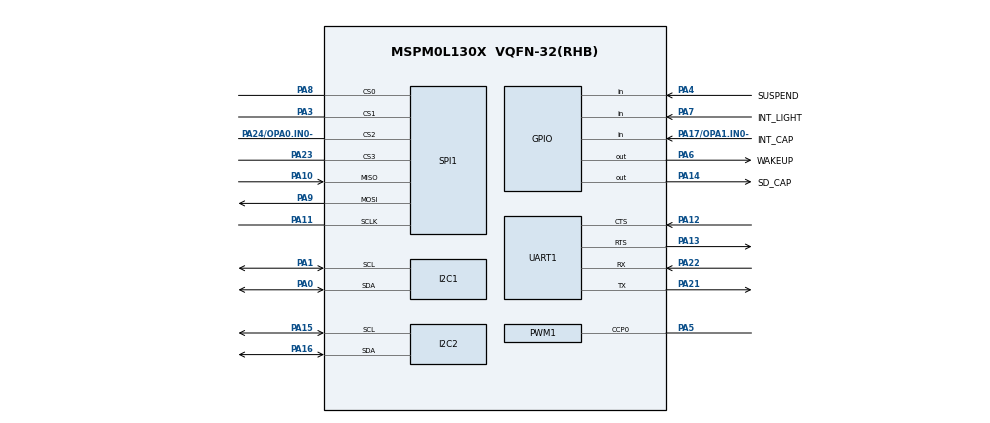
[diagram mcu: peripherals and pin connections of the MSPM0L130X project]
/**
 * @cliArgs --device "MSPM0L130X" --part "Default" --package "VQFN-32(RHB)" --product "mspm0_sdk@2.03.00.08"
 * @versions {"tool":"1.22.0+3893"}
 */

/**
 * Import the modules used in this configuration.
 */
const GPIO   = scripting.addModule("/ti/driverlib/GPIO", {}, false);
const GPIO1  = GPIO.addInstance();
const I2C    = scripting.addModule("/ti/driverlib/I2C", {}, false);
const I2C1   = I2C.addInstance();
const I2C2   = I2C.addInstance();
const PWM    = scripting.addModule("/ti/driverlib/PWM", {}, false);
const PWM1   = PWM.addInstance();
const SPI    = scripting.addModule("/ti/driverlib/SPI", {}, false);
const SPI1   = SPI.addInstance();
const SYSCTL = scripting.addModule("/ti/driverlib/SYSCTL");
const UART   = scripting.addModule("/ti/driverlib/UART", {}, false);
const UART1  = UART.addInstance();

/**
 * Write custom configuration values to the imported modules.
 */
GPIO1.$name                          = "GPIO_INT";
GPIO1.associatedPins.create(9);
GPIO1.associatedPins[0].$name        = "BUT_POS";
GPIO1.associatedPins[0].direction    = "INPUT";
GPIO1.associatedPins[0].ioStructure  = "SD";
GPIO1.associatedPins[0].assignedPin  = "27";
GPIO1.associatedPins[1].$name        = "BUT_ANZ";
GPIO1.associatedPins[1].direction    = "INPUT";
GPIO1.associatedPins[1].assignedPin  = "18";
GPIO1.associatedPins[2].$name        = "INT2_ACC";
GPIO1.associatedPins[2].direction    = "INPUT";
GPIO1.associatedPins[2].assignedPin  = "26";
GPIO1.associatedPins[3].$name        = "INT1_ACC";
GPIO1.associatedPins[3].direction    = "INPUT";
GPIO1.associatedPins[3].assignedPin  = "25";
GPIO1.associatedPins[4].$name        = "INT_CAP";
GPIO1.associatedPins[4].assignedPin  = "17";
GPIO1.associatedPins[4].direction    = "INPUT";
GPIO1.associatedPins[4].pin.$assign  = "PA17/OPA1.IN0-";
GPIO1.associatedPins[5].$name        = "SD_CAP";
GPIO1.associatedPins[5].initialValue = "SET";
GPIO1.associatedPins[5].ioStructure  = "SD";
GPIO1.associatedPins[5].pin.$assign  = "PA14";
GPIO1.associatedPins[6].$name        = "INT_LIGHT";
GPIO1.associatedPins[6].direction    = "INPUT";
GPIO1.associatedPins[6].ioStructure  = "SD";
GPIO1.associatedPins[6].pin.$assign  = "PA7";
GPIO1.associatedPins[7].$name        = "WAKEUP";
GPIO1.associatedPins[7].pin.$assign  = "PA6";
GPIO1.associatedPins[8].$name        = "SUSPEND";
GPIO1.associatedPins[8].direction    = "INPUT";
GPIO1.associatedPins[8].pin.$assign  = "PA4";

const Board = scripting.addModule("/ti/driverlib/Board", {}, false);

I2C1.$name                           = "I2C_0";
I2C1.basicEnableController           = true;
I2C1.basicControllerStandardBusSpeed = "Fast";
I2C1.peripheral.$assign              = "I2C0";
I2C1.peripheral.sdaPin.$assign       = "PA0";
I2C1.peripheral.sclPin.$assign       = "PA1";
I2C1.sdaPinConfig.$name              = "ti_driverlib_gpio_GPIOPinGeneric7";
I2C1.sclPinConfig.$name              = "ti_driverlib_gpio_GPIOPinGeneric8";

I2C2.$name                           = "I2C_1";
I2C2.basicEnableController           = true;
I2C2.basicControllerStandardBusSpeed = "Fast";
I2C2.peripheral.$assign              = "I2C1";
I2C2.peripheral.sdaPin.$assign       = "PA16";
I2C2.peripheral.sclPin.$assign       = "PA15";
I2C2.sdaPinConfig.$name              = "ti_driverlib_gpio_GPIOPinGeneric9";
I2C2.sclPinConfig.$name              = "ti_driverlib_gpio_GPIOPinGeneric10";

PWM1.$name                      = "PWM_0";
PWM1.profile                    = "basic_single_channel_center_align";
PWM1.peripheral.$assign         = "TIMG0";
PWM1.peripheral.ccp0Pin.$assign = "PA5";
PWM1.PWM_CHANNEL_0.$name        = "ti_driverlib_pwm_PWMTimerCC0";
PWM1.ccp0PinConfig.$name        = "ti_driverlib_gpio_GPIOPinGeneric15";

SPI1.$name                              = "SPI_0";
SPI1.targetBitRate                      = 1000000;
SPI1.enableDMAEvent1                    = false;
SPI1.enableDMAEvent2                    = false;
SPI1.mode                               = "CONTROLLER";
SPI1.chipSelect                         = ["0","1","2","3"];
SPI1.peripheral.sclkPin.$assign         = "PA11";
SPI1.peripheral.mosiPin.$assign         = "PA9";
SPI1.peripheral.misoPin.$assign         = "PA10";
SPI1.peripheral.cs0Pin.$assign          = "PA8";
SPI1.peripheral.cs1Pin.$assign          = "PA3";
SPI1.peripheral.cs2Pin.$assign          = "PA24/OPA0.IN0-";
SPI1.peripheral.cs3Pin.$assign          = "PA23";
SPI1.sclkPinConfig.$name                = "ti_driverlib_gpio_GPIOPinGeneric0";
SPI1.sclkPinConfig.onlyInternalResistor = scripting.forceWrite(false);
SPI1.sclkPinConfig.passedPeripheralType = scripting.forceWrite("Digital");
SPI1.mosiPinConfig.$name                = "ti_driverlib_gpio_GPIOPinGeneric1";
SPI1.mosiPinConfig.hideOutputInversion  = scripting.forceWrite(false);
SPI1.mosiPinConfig.onlyInternalResistor = scripting.forceWrite(false);
SPI1.mosiPinConfig.passedPeripheralType = scripting.forceWrite("Digital");
SPI1.misoPinConfig.$name                = "ti_driverlib_gpio_GPIOPinGeneric2";
SPI1.misoPinConfig.onlyInternalResistor = scripting.forceWrite(false);
SPI1.misoPinConfig.passedPeripheralType = scripting.forceWrite("Digital");
SPI1.cs0PinConfig.$name                 = "ti_driverlib_gpio_GPIOPinGeneric3";
SPI1.cs1PinConfig.$name                 = "ti_driverlib_gpio_GPIOPinGeneric4";
SPI1.cs2PinConfig.$name                 = "ti_driverlib_gpio_GPIOPinGeneric5";
SPI1.cs3PinConfig.$name                 = "ti_driverlib_gpio_GPIOPinGeneric6";

SYSCTL.enableROSC      = true;
SYSCTL.enableSYSOSCFCL = true;

UART1.$name                     = "UART_0";
UART1.flowControl               = "RTS_CTS";
UART1.enableDMARX               = false;
UART1.peripheral.$assign        = "UART0";
UART1.peripheral.rxPin.$assign  = "PA22";
UART1.peripheral.txPin.$assign  = "PA21";
UART1.peripheral.rtsPin.$assign = "PA13";
UART1.peripheral.ctsPin.$assign = "PA12";
UART1.txPinConfig.$name         = "ti_driverlib_gpio_GPIOPinGeneric11";
UART1.rxPinConfig.$name         = "ti_driverlib_gpio_GPIOPinGeneric12";
UART1.rtsPinConfig.$name        = "ti_driverlib_gpio_GPIOPinGeneric13";
UART1.ctsPinConfig.$name        = "ti_driverlib_gpio_GPIOPinGeneric14";

/**
 * Pinmux solution for unlocked pins/peripherals. This ensures that minor changes to the automatic solver in a future
 * version of the tool will not impact the pinmux you originally saw.  These lines can be completely deleted in order to
 * re-solve from scratch.
 */
GPIO1.associatedPins[0].pin.$suggestSolution = "PA27";
GPIO1.associatedPins[1].pin.$suggestSolution = "PA18";
GPIO1.associatedPins[2].pin.$suggestSolution = "PA26";
GPIO1.associatedPins[3].pin.$suggestSolution = "PA25";
Board.peripheral.$suggestSolution            = "DEBUGSS";
Board.peripheral.swclkPin.$suggestSolution   = "PA20";
Board.peripheral.swdioPin.$suggestSolution   = "PA19";
SPI1.peripheral.$suggestSolution             = "SPI0";
SYSCTL.peripheral.$suggestSolution           = "SYSCTL";
SYSCTL.peripheral.roscPin.$suggestSolution   = "PA2";
